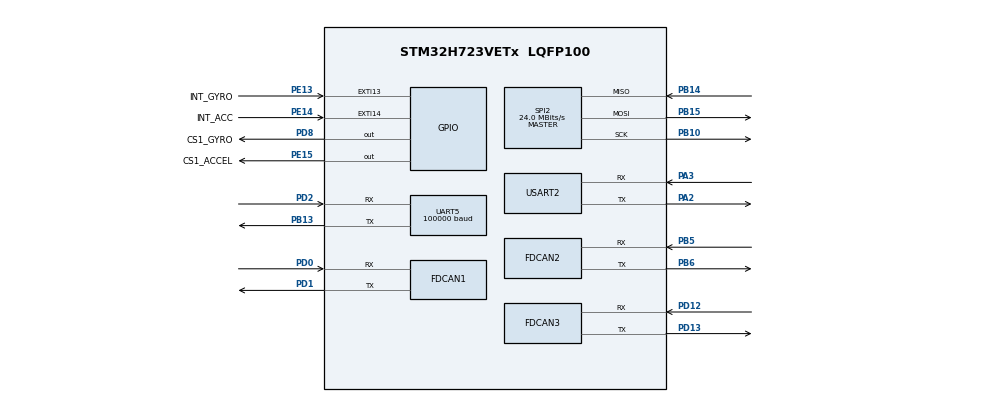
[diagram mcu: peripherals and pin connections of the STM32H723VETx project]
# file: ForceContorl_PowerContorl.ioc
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CORTEX_M7.CPU_DCache=Disabled
CORTEX_M7.CPU_ICache=Disabled
CORTEX_M7.default_mode_Activation=0
Dma.Request0=USART2_RX
Dma.Request1=USART2_TX
Dma.Request2=SPI2_RX
Dma.Request3=SPI2_TX
Dma.Request4=UART5_RX
Dma.Request5=UART5_TX
Dma.SPI2_RX.2.Direction=DMA_PERIPH_TO_MEMORY
Dma.SPI2_RX.2.EventEnable=DISABLE
Dma.SPI2_RX.2.FIFOMode=DMA_FIFOMODE_DISABLE
Dma.SPI2_RX.2.Instance=DMA1_Stream1
Dma.SPI2_RX.2.MemDataAlignment=DMA_MDATAALIGN_BYTE
Dma.SPI2_RX.2.MemInc=DMA_MINC_ENABLE
Dma.SPI2_RX.2.Mode=DMA_NORMAL
Dma.SPI2_RX.2.PeriphDataAlignment=DMA_PDATAALIGN_BYTE
Dma.SPI2_RX.2.PeriphInc=DMA_PINC_DISABLE
Dma.SPI2_RX.2.Polarity=HAL_DMAMUX_REQ_GEN_RISING
Dma.SPI2_RX.2.Priority=DMA_PRIORITY_VERY_HIGH
Dma.SPI2_RX.2.RequestNumber=1
Dma.SPI2_RX.2.SignalID=NONE
Dma.SPI2_RX.2.SyncEnable=DISABLE
Dma.SPI2_RX.2.SyncPolarity=HAL_DMAMUX_SYNC_NO_EVENT
Dma.SPI2_RX.2.SyncRequestNumber=1
Dma.SPI2_RX.2.SyncSignalID=NONE
Dma.SPI2_TX.3.Direction=DMA_MEMORY_TO_PERIPH
Dma.SPI2_TX.3.EventEnable=DISABLE
Dma.SPI2_TX.3.FIFOMode=DMA_FIFOMODE_DISABLE
Dma.SPI2_TX.3.Instance=DMA1_Stream2
Dma.SPI2_TX.3.MemDataAlignment=DMA_MDATAALIGN_BYTE
Dma.SPI2_TX.3.MemInc=DMA_MINC_ENABLE
Dma.SPI2_TX.3.Mode=DMA_NORMAL
Dma.SPI2_TX.3.PeriphDataAlignment=DMA_PDATAALIGN_BYTE
Dma.SPI2_TX.3.PeriphInc=DMA_PINC_DISABLE
Dma.SPI2_TX.3.Polarity=HAL_DMAMUX_REQ_GEN_RISING
Dma.SPI2_TX.3.Priority=DMA_PRIORITY_LOW
Dma.SPI2_TX.3.RequestNumber=1
Dma.SPI2_TX.3.SignalID=NONE
Dma.SPI2_TX.3.SyncEnable=DISABLE
Dma.SPI2_TX.3.SyncPolarity=HAL_DMAMUX_SYNC_NO_EVENT
Dma.SPI2_TX.3.SyncRequestNumber=1
Dma.SPI2_TX.3.SyncSignalID=NONE
Dma.UART5_RX.4.Direction=DMA_PERIPH_TO_MEMORY
Dma.UART5_RX.4.EventEnable=DISABLE
Dma.UART5_RX.4.FIFOMode=DMA_FIFOMODE_DISABLE
Dma.UART5_RX.4.Instance=DMA1_Stream0
Dma.UART5_RX.4.MemDataAlignment=DMA_MDATAALIGN_BYTE
Dma.UART5_RX.4.MemInc=DMA_MINC_ENABLE
Dma.UART5_RX.4.Mode=DMA_CIRCULAR
Dma.UART5_RX.4.PeriphDataAlignment=DMA_PDATAALIGN_BYTE
Dma.UART5_RX.4.PeriphInc=DMA_PINC_DISABLE
Dma.UART5_RX.4.Polarity=HAL_DMAMUX_REQ_GEN_RISING
Dma.UART5_RX.4.Priority=DMA_PRIORITY_VERY_HIGH
Dma.UART5_RX.4.RequestNumber=1
Dma.UART5_RX.4.SignalID=NONE
Dma.UART5_RX.4.SyncEnable=DISABLE
Dma.UART5_RX.4.SyncPolarity=HAL_DMAMUX_SYNC_NO_EVENT
Dma.UART5_RX.4.SyncRequestNumber=1
Dma.UART5_RX.4.SyncSignalID=NONE
Dma.UART5_TX.5.Direction=DMA_MEMORY_TO_PERIPH
Dma.UART5_TX.5.EventEnable=DISABLE
Dma.UART5_TX.5.FIFOMode=DMA_FIFOMODE_DISABLE
Dma.UART5_TX.5.Instance=DMA1_Stream5
Dma.UART5_TX.5.MemDataAlignment=DMA_MDATAALIGN_BYTE
Dma.UART5_TX.5.MemInc=DMA_MINC_ENABLE
Dma.UART5_TX.5.Mode=DMA_CIRCULAR
Dma.UART5_TX.5.PeriphDataAlignment=DMA_PDATAALIGN_BYTE
Dma.UART5_TX.5.PeriphInc=DMA_PINC_DISABLE
Dma.UART5_TX.5.Polarity=HAL_DMAMUX_REQ_GEN_RISING
Dma.UART5_TX.5.Priority=DMA_PRIORITY_LOW
Dma.UART5_TX.5.RequestNumber=1
Dma.UART5_TX.5.SignalID=NONE
Dma.UART5_TX.5.SyncEnable=DISABLE
Dma.UART5_TX.5.SyncPolarity=HAL_DMAMUX_SYNC_NO_EVENT
Dma.UART5_TX.5.SyncRequestNumber=1
Dma.UART5_TX.5.SyncSignalID=NONE
Dma.USART2_RX.0.Direction=DMA_PERIPH_TO_MEMORY
Dma.USART2_RX.0.EventEnable=DISABLE
Dma.USART2_RX.0.FIFOMode=DMA_FIFOMODE_DISABLE
Dma.USART2_RX.0.Instance=DMA1_Stream4
Dma.USART2_RX.0.MemDataAlignment=DMA_MDATAALIGN_BYTE
Dma.USART2_RX.0.MemInc=DMA_MINC_ENABLE
Dma.USART2_RX.0.Mode=DMA_CIRCULAR
Dma.USART2_RX.0.PeriphDataAlignment=DMA_PDATAALIGN_BYTE
Dma.USART2_RX.0.PeriphInc=DMA_PINC_DISABLE
Dma.USART2_RX.0.Polarity=HAL_DMAMUX_REQ_GEN_RISING
Dma.USART2_RX.0.Priority=DMA_PRIORITY_LOW
Dma.USART2_RX.0.RequestNumber=1
Dma.USART2_RX.0.SignalID=NONE
Dma.USART2_RX.0.SyncEnable=DISABLE
Dma.USART2_RX.0.SyncPolarity=HAL_DMAMUX_SYNC_NO_EVENT
Dma.USART2_RX.0.SyncRequestNumber=1
Dma.USART2_RX.0.SyncSignalID=NONE
Dma.USART2_TX.1.Direction=DMA_MEMORY_TO_PERIPH
Dma.USART2_TX.1.EventEnable=DISABLE
Dma.USART2_TX.1.FIFOMode=DMA_FIFOMODE_DISABLE
Dma.USART2_TX.1.Instance=DMA1_Stream3
Dma.USART2_TX.1.MemDataAlignment=DMA_MDATAALIGN_BYTE
Dma.USART2_TX.1.MemInc=DMA_MINC_ENABLE
Dma.USART2_TX.1.Mode=DMA_CIRCULAR
Dma.USART2_TX.1.PeriphDataAlignment=DMA_PDATAALIGN_BYTE
Dma.USART2_TX.1.PeriphInc=DMA_PINC_DISABLE
Dma.USART2_TX.1.Polarity=HAL_DMAMUX_REQ_GEN_RISING
Dma.USART2_TX.1.Priority=DMA_PRIORITY_LOW
Dma.USART2_TX.1.RequestNumber=1
Dma.USART2_TX.1.SignalID=NONE
Dma.USART2_TX.1.SyncEnable=DISABLE
Dma.USART2_TX.1.SyncPolarity=HAL_DMAMUX_SYNC_NO_EVENT
Dma.USART2_TX.1.SyncRequestNumber=1
Dma.USART2_TX.1.SyncSignalID=NONE
FDCAN1.AutoRetransmission=ENABLE
FDCAN1.CalculateBaudRateNominal=1000000
FDCAN1.CalculateTimeBitNominal=1000
FDCAN1.CalculateTimeQuantumNominal=25.0
FDCAN1.DataPrescaler=3
FDCAN1.DataSyncJumpWidth=10
FDCAN1.DataTimeSeg1=29
FDCAN1.DataTimeSeg2=10
FDCAN1.NominalPrescaler=3
FDCAN1.NominalSyncJumpWidth=10
FDCAN1.NominalTimeSeg1=29
FDCAN1.NominalTimeSeg2=10
FDCAN1.ProtocolException=ENABLE
FDCAN1.RxFifo0ElmtsNbr=4
FDCAN1.StdFiltersNbr=1
FDCAN1.TxFifoQueueElmtsNbr=4
FDCAN2.AutoRetransmission=ENABLE
FDCAN2.CalculateBaudRateNominal=1000000
FDCAN2.CalculateTimeBitNominal=1000
FDCAN2.CalculateTimeQuantumNominal=25.0
FDCAN2.DataPrescaler=3
FDCAN2.DataSyncJumpWidth=10
FDCAN2.DataTimeSeg1=29
FDCAN2.DataTimeSeg2=10
FDCAN2.MessageRAMOffset=800
FDCAN2.NominalPrescaler=3
FDCAN2.NominalSyncJumpWidth=10
FDCAN2.NominalTimeSeg1=29
FDCAN2.NominalTimeSeg2=10
FDCAN2.ProtocolException=ENABLE
FDCAN2.RxFifo0ElmtsNbr=16
FDCAN2.StdFiltersNbr=1
FDCAN2.TxFifoQueueElmtsNbr=16
FDCAN3.AutoRetransmission=ENABLE
FDCAN3.CalculateBaudRateNominal=1000000
FDCAN3.CalculateTimeBitNominal=1000
FDCAN3.CalculateTimeQuantumNominal=25.0
FDCAN3.DataPrescaler=3
FDCAN3.DataSyncJumpWidth=10
FDCAN3.DataTimeSeg1=29
FDCAN3.DataTimeSeg2=10
FDCAN3.MessageRAMOffset=1600
FDCAN3.NominalPrescaler=3
FDCAN3.NominalSyncJumpWidth=10
FDCAN3.NominalTimeSeg1=29
FDCAN3.NominalTimeSeg2=10
FDCAN3.ProtocolException=ENABLE
FDCAN3.RxFifo0ElmtsNbr=4
FDCAN3.StdFiltersNbr=1
FDCAN3.TxFifoQueueElmtsNbr=4
FREERTOS.Tasks01=defaultTask,0,512,StartDefaultTask,Default,NULL,Dynamic,NULL,NULL;SafeTask,0,512,Safe_Task,As external,NULL,Dynamic,NULL,NULL;chassistask,0,1024,chassis_task,As external,NULL,Dynamic,NULL,NULL
Mcu.Family=STM32H7
Mcu.Name=STM32H723VETx
Mcu.Package=LQFP100
NVIC.DMA1_Stream0_IRQn=true\:0\:0\:false\:false\:true\:false\:false\:true\:true
NVIC.DMA1_Stream1_IRQn=true\:5\:0\:false\:false\:true\:true\:false\:true\:true
NVIC.DMA1_Stream2_IRQn=true\:5\:0\:false\:false\:true\:true\:false\:true\:true
NVIC.DMA1_Stream3_IRQn=true\:5\:0\:false\:false\:true\:true\:false\:true\:true
NVIC.DMA1_Stream4_IRQn=true\:5\:0\:false\:false\:true\:true\:false\:true\:true
NVIC.DMA1_Stream5_IRQn=true\:5\:0\:false\:false\:true\:true\:false\:true\:true
NVIC.FDCAN1_IT0_IRQn=true\:5\:0\:false\:false\:true\:true\:true\:true\:true
NVIC.FDCAN1_IT1_IRQn=true\:5\:0\:false\:false\:true\:true\:true\:true\:true
NVIC.FDCAN2_IT0_IRQn=true\:5\:0\:false\:false\:true\:true\:true\:true\:true
NVIC.FDCAN2_IT1_IRQn=true\:5\:0\:false\:false\:true\:true\:true\:true\:true
NVIC.FDCAN3_IT0_IRQn=true\:5\:0\:false\:false\:true\:true\:true\:true\:true
NVIC.FDCAN3_IT1_IRQn=true\:5\:0\:false\:false\:true\:true\:true\:true\:true
NVIC.PriorityGroup=NVIC_PRIORITYGROUP_4
NVIC.SPI2_IRQn=true\:5\:0\:false\:false\:true\:true\:false\:true\:true
NVIC.TIM2_IRQn=true\:15\:0\:false\:false\:true\:false\:false\:true\:true
NVIC.TimeBase=TIM2_IRQn
NVIC.TimeBaseIP=TIM2
NVIC.UART5_IRQn=true\:5\:0\:false\:false\:true\:true\:true\:true\:true
NVIC.USART2_IRQn=true\:5\:0\:false\:false\:true\:true\:false\:true\:true
PA13(JTMS/SWDIO).Mode=Serial_Wire
PA13(JTMS/SWDIO).Signal=DEBUG_JTMS-SWDIO
PA14(JTCK/SWCLK).Mode=Serial_Wire
PA14(JTCK/SWCLK).Signal=DEBUG_JTCK-SWCLK
PA2.Mode=Asynchronous
PA2.Signal=USART2_TX
PA3.Mode=Asynchronous
PA3.Signal=USART2_RX
PB10.Mode=Full_Duplex_Master
PB10.Signal=SPI2_SCK
PB13.Mode=Asynchronous
PB13.Signal=UART5_TX
PB14.Mode=Full_Duplex_Master
PB14.Signal=SPI2_MISO
PB15.Mode=Full_Duplex_Master
PB15.Signal=SPI2_MOSI
PB5.Mode=FDCAN_Activate
PB5.Signal=FDCAN2_RX
PB6.Mode=FDCAN_Activate
PB6.Signal=FDCAN2_TX
PC14-OSC32_IN.Mode=LSE-External-Oscillator
PC14-OSC32_IN.Signal=RCC_OSC32_IN
PC15-OSC32_OUT.Mode=LSE-External-Oscillator
PC15-OSC32_OUT.Signal=RCC_OSC32_OUT
PD0.Mode=FDCAN_Activate
PD0.Signal=FDCAN1_RX
PD1.Mode=FDCAN_Activate
PD1.Signal=FDCAN1_TX
PD12.Mode=FDCAN_Activate
PD12.Signal=FDCAN3_RX
PD13.Mode=FDCAN_Activate
PD13.Signal=FDCAN3_TX
PD2.GPIO_Speed=GPIO_SPEED_FREQ_LOW
PD2.Mode=Asynchronous
PD2.Signal=UART5_RX
PD8.GPIO_Label=CS1_GYRO
PD8.GPIO_PuPd=GPIO_PULLUP
PD8.GPIO_Speed=GPIO_SPEED_FREQ_MEDIUM
PD8.PinState=GPIO_PIN_SET
PD8.Signal=GPIO_Output
PE13.GPIO_Label=INT_GYRO
PE13.Signal=GPXTI13
PE14.GPIO_Label=INT_ACC
PE14.Signal=GPXTI14
PE15.GPIO_Label=CS1_ACCEL
PE15.GPIO_PuPd=GPIO_PULLUP
PE15.GPIO_Speed=GPIO_SPEED_FREQ_MEDIUM
PE15.PinState=GPIO_PIN_SET
PE15.Signal=GPIO_Output
PH0-OSC_IN.Mode=HSE-External-Oscillator
PH0-OSC_IN.Signal=RCC_OSC_IN
PH1-OSC_OUT.Mode=HSE-External-Oscillator
PH1-OSC_OUT.Signal=RCC_OSC_OUT
ProjectManager.HeapSize=0x2000
ProjectManager.StackSize=0x4000
ProjectManager.TargetToolchain=CMake
RCC.ADCFreq_Value=192000000
RCC.APB1Freq_Value=120000000
RCC.APB2Freq_Value=120000000
RCC.APB3Freq_Value=120000000
RCC.APB4Freq_Value=120000000
RCC.CortexFreq_Value=240000000
RCC.D1PPRE=RCC_APB3_DIV2
RCC.D2PPRE1=RCC_APB1_DIV2
RCC.D2PPRE2=RCC_APB2_DIV2
RCC.D3PPRE=RCC_APB4_DIV2
RCC.DIVM1=2
RCC.DIVM2=2
RCC.DIVM3=30
RCC.DIVN1=20
RCC.DIVN2=16
RCC.DIVP1=1
RCC.DIVP2=1
RCC.HCLKFreq_Value=240000000
RCC.HSE_VALUE=24000000
RCC.PLL2FRACN=0
RCC.PLLFRACN=0
RCC.PLLSourceVirtual=RCC_PLLSOURCE_HSE
RCC.SPI123CLockSelection=RCC_SPI123CLKSOURCE_PLL2
RCC.SYSCLKFreq_VALUE=240000000
RCC.SYSCLKSource=RCC_SYSCLKSOURCE_PLLCLK
RCC.USBFreq_Value=120000000
SPI2.BaudRatePrescaler=SPI_BAUDRATEPRESCALER_8
SPI2.CLKPhase=SPI_PHASE_2EDGE
SPI2.CLKPolarity=SPI_POLARITY_HIGH
SPI2.CalculateBaudRate=24.0 MBits/s
SPI2.DataSize=SPI_DATASIZE_8BIT
SPI2.Direction=SPI_DIRECTION_2LINES
SPI2.Mode=SPI_MODE_MASTER
SPI2.NSSPMode=SPI_NSS_PULSE_DISABLE
SPI2.VirtualType=VM_MASTER
STMicroelectronics.X-CUBE-ALGOBUILD.1.4.0.LibraryCcDSPOoLibraryJjDSPOoLibrary=true
UART5.BaudRate=100000
UART5.Mode=MODE_TX_RX
UART5.OverrunDisableParam=UART_ADVFEATURE_OVERRUN_ENABLE
UART5.Parity=PARITY_EVEN
UART5.StopBits=UART_STOPBITS_2
UART5.WordLength=WORDLENGTH_9B
USART2.VirtualMode-Asynchronous=VM_ASYNC
VP_FREERTOS_VS_CMSIS_V1.Mode=CMSIS_V1
VP_MEMORYMAP_VS_MEMORYMAP.Mode=CurAppReg
VP_STMicroelectronics.X-CUBE-ALGOBUILD_VS_DSPOoLibraryJjLibrary_1.4.0_1.4.0.Mode=DSPOoLibraryJjLibrary
VP_SYS_VS_tim2.Mode=TIM2
board=custom

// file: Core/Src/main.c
/* USER CODE BEGIN Header */
/**
  ******************************************************************************
  * @file           : main.c
  * @brief          : Main program body
  ******************************************************************************
  * @attention
  *
  * Copyright (c) 2025 STMicroelectronics.
  * All rights reserved.
  *
  * This software is licensed under terms that can be found in the LICENSE file
  * in the root directory of this software component.
  * If no LICENSE file comes with this software, it is provided AS-IS.
  *
  ******************************************************************************
  */
/* USER CODE END Header */
#include "main.h"
#include "cmsis_os.h"
#include "dma.h"
#include "fdcan.h"
#include "memorymap.h"
#include "spi.h"
#include "usart.h"
#include "gpio.h"

/* USER CODE BEGIN Includes */
extern void task_init(void);
/* USER CODE END Includes */

void SystemClock_Config(void);
static void MPU_Config(void);
void MX_FREERTOS_Init(void);

int main(void)
{

  /* MPU Configuration--------------------------------------------------------*/
  MPU_Config();

  /* MCU Configuration--------------------------------------------------------*/

  /* Reset of all peripherals, Initializes the Flash interface and the Systick. */
  HAL_Init();

  /* Configure the system clock */
  SystemClock_Config();

  /* Initialize all configured peripherals */
  MX_GPIO_Init();
  MX_DMA_Init();
  MX_FDCAN1_Init();
  MX_FDCAN2_Init();
  MX_FDCAN3_Init();
  MX_UART5_Init();
  MX_USART2_UART_Init();
  MX_SPI2_Init();
  /* USER CODE BEGIN 2 */
  task_init();
  /* USER CODE END 2 */

  /* Call init function for freertos objects (in cmsis_os2.c) */
  MX_FREERTOS_Init();

  /* Start scheduler */
  osKernelStart();

  /* We should never get here as control is now taken by the scheduler */

  /* Infinite loop */
  while (1)
  {

  }
}

void SystemClock_Config(void)
{
  RCC_OscInitTypeDef RCC_OscInitStruct = {0};
  RCC_ClkInitTypeDef RCC_ClkInitStruct = {0};

  /** Supply configuration update enable
  */
  HAL_PWREx_ConfigSupply(PWR_LDO_SUPPLY);

  /** Configure the main internal regulator output voltage
  */
  __HAL_PWR_VOLTAGESCALING_CONFIG(PWR_REGULATOR_VOLTAGE_SCALE0);

  while(!__HAL_PWR_GET_FLAG(PWR_FLAG_VOSRDY)) {}

  /** Initializes the RCC Oscillators according to the specified parameters
  * in the RCC_OscInitTypeDef structure.
  */
  RCC_OscInitStruct.OscillatorType = RCC_OSCILLATORTYPE_HSE;
  RCC_OscInitStruct.HSEState = RCC_HSE_ON;
  RCC_OscInitStruct.PLL.PLLState = RCC_PLL_ON;
  RCC_OscInitStruct.PLL.PLLSource = RCC_PLLSOURCE_HSE;
  RCC_OscInitStruct.PLL.PLLM = 2;
  RCC_OscInitStruct.PLL.PLLN = 20;
  RCC_OscInitStruct.PLL.PLLP = 1;
  RCC_OscInitStruct.PLL.PLLQ = 2;
  RCC_OscInitStruct.PLL.PLLR = 2;
  RCC_OscInitStruct.PLL.PLLRGE = RCC_PLL1VCIRANGE_3;
  RCC_OscInitStruct.PLL.PLLVCOSEL = RCC_PLL1VCOWIDE;
  RCC_OscInitStruct.PLL.PLLFRACN = 0;
  if (HAL_RCC_OscConfig(&RCC_OscInitStruct) != HAL_OK)
  {
    Error_Handler();
  }

  /** Initializes the CPU, AHB and APB buses clocks
  */
  RCC_ClkInitStruct.ClockType = RCC_CLOCKTYPE_HCLK|RCC_CLOCKTYPE_SYSCLK
                              |RCC_CLOCKTYPE_PCLK1|RCC_CLOCKTYPE_PCLK2
                              |RCC_CLOCKTYPE_D3PCLK1|RCC_CLOCKTYPE_D1PCLK1;
  RCC_ClkInitStruct.SYSCLKSource = RCC_SYSCLKSOURCE_PLLCLK;
  RCC_ClkInitStruct.SYSCLKDivider = RCC_SYSCLK_DIV1;
  RCC_ClkInitStruct.AHBCLKDivider = RCC_HCLK_DIV1;
  RCC_ClkInitStruct.APB3CLKDivider = RCC_APB3_DIV2;
  RCC_ClkInitStruct.APB1CLKDivider = RCC_APB1_DIV2;
  RCC_ClkInitStruct.APB2CLKDivider = RCC_APB2_DIV2;
  RCC_ClkInitStruct.APB4CLKDivider = RCC_APB4_DIV2;

  if (HAL_RCC_ClockConfig(&RCC_ClkInitStruct, FLASH_LATENCY_3) != HAL_OK)
  {
    Error_Handler();
  }
}

 /* MPU Configuration */

void MPU_Config(void)
{
  MPU_Region_InitTypeDef MPU_InitStruct = {0};

  /* Disables the MPU */
  HAL_MPU_Disable();

  /** Initializes and configures the Region and the memory to be protected
  */
  MPU_InitStruct.Enable = MPU_REGION_ENABLE;
  MPU_InitStruct.Number = MPU_REGION_NUMBER0;
  MPU_InitStruct.BaseAddress = 0x0;
  MPU_InitStruct.Size = MPU_REGION_SIZE_4GB;
  MPU_InitStruct.SubRegionDisable = 0x87;
  MPU_InitStruct.TypeExtField = MPU_TEX_LEVEL0;
  MPU_InitStruct.AccessPermission = MPU_REGION_NO_ACCESS;
  MPU_InitStruct.DisableExec = MPU_INSTRUCTION_ACCESS_DISABLE;
  MPU_InitStruct.IsShareable = MPU_ACCESS_SHAREABLE;
  MPU_InitStruct.IsCacheable = MPU_ACCESS_NOT_CACHEABLE;
  MPU_InitStruct.IsBufferable = MPU_ACCESS_NOT_BUFFERABLE;

  HAL_MPU_ConfigRegion(&MPU_InitStruct);
  /* Enables the MPU */
  HAL_MPU_Enable(MPU_PRIVILEGED_DEFAULT);

}

void HAL_TIM_PeriodElapsedCallback(TIM_HandleTypeDef *htim)
{
  if (htim->Instance == TIM2) {
    HAL_IncTick();
  }
}

void Error_Handler(void)
{
  __disable_irq();
  while (1)
  {
  }
}

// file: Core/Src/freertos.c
/* USER CODE BEGIN Header */
/**
  ******************************************************************************
  * File Name          : freertos.c
  * Description        : Code for freertos applications
  ******************************************************************************
  * @attention
  *
  * Copyright (c) 2025 STMicroelectronics.
  * All rights reserved.
  *
  * This software is licensed under terms that can be found in the LICENSE file
  * in the root directory of this software component.
  * If no LICENSE file comes with this software, it is provided AS-IS.
  *
  ******************************************************************************
  */
/* USER CODE END Header */

#include "FreeRTOS.h"
#include "task.h"
#include "main.h"
#include "cmsis_os.h"

osThreadId defaultTaskHandle;
osThreadId SafeTaskHandle;
osThreadId chassistaskHandle;

void StartDefaultTask(void const * argument);
extern void Safe_Task(void const * argument);
extern void chassis_task(void const * argument);

void MX_FREERTOS_Init(void); /* (MISRA C 2004 rule 8.1) */

/* GetIdleTaskMemory prototype (linked to static allocation support) */
void vApplicationGetIdleTaskMemory( StaticTask_t **ppxIdleTaskTCBBuffer, StackType_t **ppxIdleTaskStackBuffer, uint32_t *pulIdleTaskStackSize );

/* USER CODE BEGIN GET_IDLE_TASK_MEMORY */
static StaticTask_t xIdleTaskTCBBuffer;
static StackType_t xIdleStack[configMINIMAL_STACK_SIZE];

void vApplicationGetIdleTaskMemory( StaticTask_t **ppxIdleTaskTCBBuffer, StackType_t **ppxIdleTaskStackBuffer, uint32_t *pulIdleTaskStackSize )
{
  *ppxIdleTaskTCBBuffer = &xIdleTaskTCBBuffer;
  *ppxIdleTaskStackBuffer = &xIdleStack[0];
  *pulIdleTaskStackSize = configMINIMAL_STACK_SIZE;
  /* place for user code */
}
/* USER CODE END GET_IDLE_TASK_MEMORY */

void MX_FREERTOS_Init(void) {

  /* Create the thread(s) */
  /* definition and creation of defaultTask */
  osThreadDef(defaultTask, StartDefaultTask, osPriorityNormal, 0, 512);
  defaultTaskHandle = osThreadCreate(osThread(defaultTask), NULL);

  /* definition and creation of SafeTask */
  osThreadDef(SafeTask, Safe_Task, osPriorityNormal, 0, 512);
  SafeTaskHandle = osThreadCreate(osThread(SafeTask), NULL);

  /* definition and creation of chassistask */
  osThreadDef(chassistask, chassis_task, osPriorityNormal, 0, 1024);
  chassistaskHandle = osThreadCreate(osThread(chassistask), NULL);

}

void StartDefaultTask(void const * argument)
{
  for(;;)
  {
    osDelay(1);
  }
}
